# STM32G553 register map
File version: 2.0.0
CPU: CM33 r0p4, little endian, MPU, FPU, 4 interrupt priority bits
Registers are 32-bit, read-write, reset 0x0 unless marked. A register's access mark holds for its fields unless they carry their own. Offsets are from the block's base; [hi:lo] are bit positions; {n}, {i} and the like mark numbered series.

## POSENC1 — POSENC register block
Base 0x44010000
Same registers: POSENC2 0x44014000, POSENC1_S 0x54010000, POSENC2_S 0x54014000
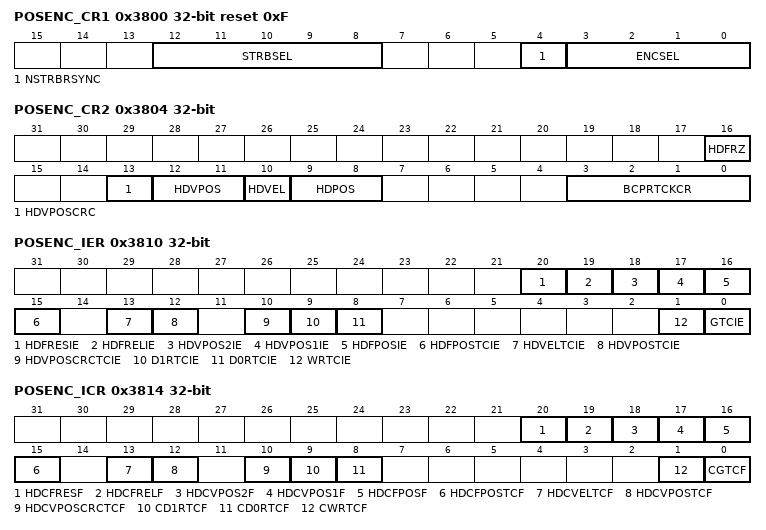
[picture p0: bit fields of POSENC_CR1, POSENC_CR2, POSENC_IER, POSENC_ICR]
0x3800 POSENC_CR1 rw-once reset 0xF — POSENC control register 1
  [12:8] STRBSEL rw — Strobe selection
    0=posenc_strb0; 1=posenc_strb1; 31=posenc_strb31
  [4] NSTRBRSYNC rw — Strobe re-synchronization
    0=Strobe re-synchronization enabled; 1=Strobe re-synchronization disabled
  [3:0] ENCSEL — Encoder selection
    0=EnDat3; 4=Hiperface-DSL; 15=No protocol selected
0x3804 POSENC_CR2 rw-once — POSENC control register 2
  [16] HDFRZ rw — Hiperface-DSL freeze
    0=Hiperface-DSL registers are not freezed; 1=Hiperface-DSL registers are freezed
  [13] HDVPOSCRC rw — Hiperface-DSL velocity event-driven accesses
    0=No safe position 1 CRC reading; 1=Safe position 1 CRC reading (VPOSCRC stored in POSENC_HD_VPOSCRC)
  [12:11] HDVPOS rw — Hiperface-DSL fast position event-driven accesses
    0=No safe position 1 reading; 1=Single-turn 17-bit safe position 1 reading (VPOS0..2 stored in POSENC_HD_VPOS3_0); 2=Single-turn 17-bit/multi-turn 12-bit safe position 1 reading (VPOS0..3 stored in POSENC_HD_VPOS3_0); 3=Single-turn 23-bit/multi-turn 12-bit safe position 1 reading (VPOS0..4 stored in POSENC_HD_VPOS3_0 and POSENC_HD_VPOS4)
  [10] HDVEL rw — Hiperface-DSL Velocity event-driven accesses
    0=No velocity reading; 1=Velocity reading (VEL0..2 stored in POSENC_HD_VEL2_0)
  [9:8] HDPOS rw — Hiperface-DSL fast position event-driven accesses
    0=No position reading; 1=Single-turn 17-bit position reading (POS0..2 stored in POSENC_HD_POS3_0); 2=Single-turn 17-bit/multi-turn 12-bit position reading (POS0..3 stored in POSENC_HD_POS3_0); 3=Single-turn 23-bit/multi-turn 12-bit position reading (POS0..4 stored in POSENC_HD_POS3_0 and POSENC_HD_POS4)
  [3:0] BCPRTCKCR — Biss-C specific
0x3810 POSENC_IER — POSENC interrupt enable register
  [20] HDFRESIE — Hiperface-DSL short message interrupt enable
    0=Hiperface-DSL short message interrupt disabled; 1=Hiperface-DSL short message interrupt enabled
  [19] HDFRELIE — Hiperface-DSL long message interrupt enable
    0=Hiperface-DSL long message interrupt disabled; 1=Hiperface-DSL long message interrupt enabled
  [18] HDVPOS2IE — Hiperface-DSL safe position 2 interrupt enable
    0=Hiperface-DSL safe position 2 interrupt disabled; 1=Hiperface-DSL safe position 2 interrupt enabled
  [17] HDVPOS1IE — Hiperface-DSL safe position 1 interrupt enable
    0=Hiperface-DSL safe position 1 interrupt disabled; 1=Hiperface-DSL safe position 1 interrupt enabled
  [16] HDFPOSIE — Hiperface-DSL fast position interrupt enable
    0=Hiperface-DSL fast position interrupt disabled; 1=Hiperface-DSL fast position interrupt enabled
  [15] HDFPOSTCIE — Hiperface-DSL fast position transfer complete interrupt enable
    0=Hiperface-DSL fast position transfer complete interrupt disabled; 1=Hiperface-DSL fast position transfer complete interrupt enabled
  [13] HDVELTCIE — Hiperface-DSL velocity transfer complete interrupt enable
    0=Hiperface-DSL velocity transfer complete interrupt disabled; 1=Hiperface-DSL velocity transfer complete interrupt enabled
  [12] HDVPOSTCIE — Hiperface-DSL safe position 1 transfer complete interrupt enable
    0=Hiperface-DSL safe position 1 transfer complete interrupt disabled; 1=Hiperface-DSL safe position 1 transfer complete interrupt enabled
  [10] HDVPOSCRCTCIE — Hiperface-DSL safe position 1 CRC transfer complete interrupt enable
    0=Hiperface-DSL safe position 1 CRC transfer complete interrupt disabled; 1=Hiperface-DSL safe position 1 CRC transfer complete interrupt enabled
  [9] D1RTCIE — Data 1 Read transfer complete interrupt enable
    0=Data 1 transfer complete interrupt disabled; 1=Data 1 transfer complete interrupt enabled
  [8] D0RTCIE — Read Data 0 transfer complete interrupt enable
    0=Data 0 transfer complete interrupt disabled; 1=Data 0 transfer complete interrupt enabled
  [1] WRTCIE — Write transfer complete interrupt enable
    0=Write transfer complete interrupt disabled; 1=Write transfer complete interrupt enabled
  [0] GTCIE — Global Transfer complete interrupt enable
    0=Global transfer complete interrupt disabled; 1=Global transfer complete interrupt enabled
0x3814 POSENC_ICR wo — POSENC interrupt clear register
  [20] HDCFRESF — Clear Hiperface-DSL short message interrupt flag
  [19] HDCFRELF — Clear Hiperface-DSL long message interrupt flag
  [18] HDCVPOS2F — Clear Hiperface-DSL safe position 2 interrupt flag
  [17] HDCVPOS1F — Clear Hiperface-DSL safe position 1 interrupt flag
  [16] HDCFPOSF — Clear Hiperface-DSL fast position interrupt flag
  [15] HDCFPOSTCF — Clear Hiperface-DSL fast position transfer complete interrupt flag
  [13] HDCVELTCF — Clear Hiperface-DSL velocity transfer complete interrupt flag
  [12] HDCVPOSTCF — Clear Hiperface-DSL safe position 1 transfer complete interrupt flag
  [10] HDCVPOSCRCTCF — Clear Hiperface-DSL safe position 1 CRC transfer complete interrupt flag
  [9] CD1RTCF — Clear data 1 read transfer complete interrupt flag
  [8] CD0RTCF — Clear data 0 read transfer complete interrupt flag
  [1] CWRTCF — Clear write transfer complete interrupt flag
  [0] CGTCF — Clear transfer complete interrupt flag
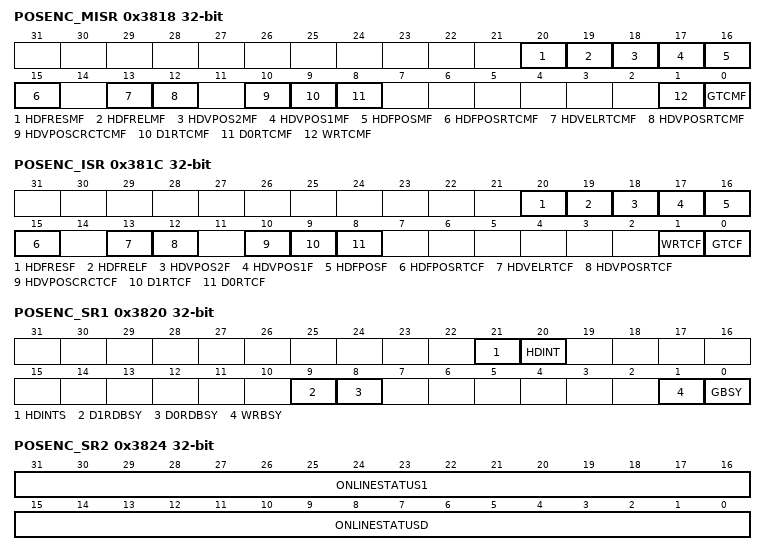
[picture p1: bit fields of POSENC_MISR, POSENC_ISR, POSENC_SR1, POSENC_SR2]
0x3818 POSENC_MISR — POSENC masked interrupt status register
  [20] HDFRESMF wo — Hiperface-DSL short message interrupt masked flag
  [19] HDFRELMF wo — Hiperface-DSL long message interrupt masked flag
  [18] HDVPOS2MF wo — Hiperface-DSL safe position 2 interrupt masked flag
  [17] HDVPOS1MF wo — Hiperface-DSL safe position 1 interrupt masked flag
  [16] HDFPOSMF wo — Hiperface-DSL fast position interrupt masked flag
  [15] HDFPOSRTCMF ro — Hiperface-DSL fast position 1 ready interrupt masked flag
  [13] HDVELRTCMF ro — Hiperface-DSL velocity ready interrupt masked flag
  [12] HDVPOSRTCMF ro — Hiperface-DSL safe position 1 transfer complete interrupt masked flag
  [10] HDVPOSCRCTCMF ro — Hiperface-DSL safe position 1 CRC transfer complete interrupt masked flag
  [9] D1RTCMF ro — Data 1 read transfer complete masked flag
  [8] D0RTCMF ro — Data 0 read transfer complete masked flag
  [1] WRTCMF ro — Write transfer complete masked flag
  [0] GTCMF ro — Global Transfer complete masked flag
0x381C POSENC_ISR — POSENC interrupt status register
  [20] HDFRESF wo — Hiperface-DSL short message interrupt flag
  [19] HDFRELF wo — Hiperface-DSL long message interrupt masked flag
  [18] HDVPOS2F wo — Hiperface-DSL safe position 2 interrupt flag
  [17] HDVPOS1F wo — Hiperface-DSL safe position 1 interrupt flag
  [16] HDFPOSF wo — Hiperface-DSL fast position interrupt flag
  [15] HDFPOSRTCF ro — Hiperface-DSL fast position transfer complete interrupt flag
  [13] HDVELRTCF ro — Hiperface-DSL velocity transfer complete interrupt flag
  [12] HDVPOSRTCF ro — Hiperface-DSL safe position 1 transfer complete interrupt flag
  [10] HDVPOSCRCTCF ro — Hiperface-DSL safe position 1 CRC transfer complete interrupt flag
  [9] D1RTCF ro — Data 1 read transfer complete flag
  [8] D0RTCF ro — Data 0 read transfer complete flag
  [1] WRTCF ro — Write transfer complete flag
  [0] GTCF ro — Global transfer complete flag
0x3820 POSENC_SR1 ro — POSENC interrupt status register 1
  [21] HDINTS — Hiperface-DSL interrupt_s line status
  [20] HDINT — Hiperface-DSL interrupt line status
  [9] D1RDBSY — Data 1 read busy
  [8] D0RDBSY — Data 0 read busy
  [1] WRBSY — Write busy
  [0] GBSY — Global busy
0x3824 POSENC_SR2 ro — POSENC interrupt status register 2
  [31:16] ONLINESTATUS1 — Online status safe 1 interface
  [15:0] ONLINESTATUSD — Online status safe 1 interface
0x3828 POSENC_SR3 ro — POSENC interrupt status register 3
  [15:0] ONLINESTATUS2 — Online status safe 2 interface
0x3A04 POSENC_D0AR — POSENC data 0 address register
  [7:0] D0ADD — Data 0 address
0x3A08 POSENC_D1AR — POSENC data 1 address register
  [7:0] D1ADD — Data 1 address
0x3B04 POSENC_D0R ro — POSENC data 0 register
  [31:0] D0 — Data 0 value
0x3B08 POSENC_D1R ro — POSENC data 1 register
  [31:0] D1 — Data 1 value
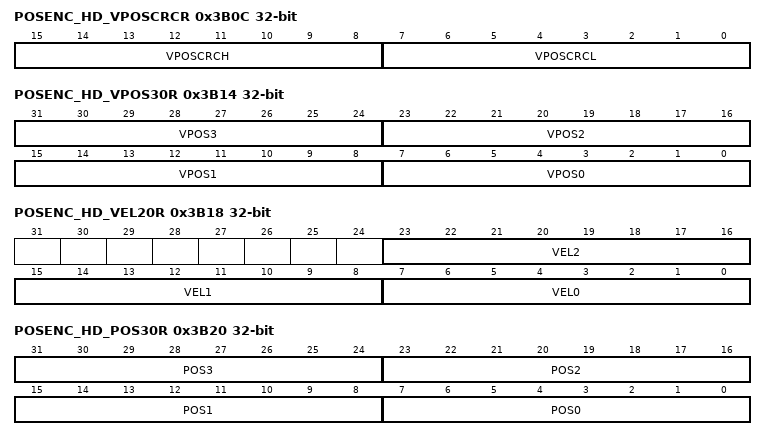
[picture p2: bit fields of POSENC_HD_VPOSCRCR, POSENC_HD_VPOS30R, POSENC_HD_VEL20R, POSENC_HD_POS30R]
0x3B0C POSENC_HD_VPOSCRCR ro — POSENC Hiperface-DSL safe position 1 CRC register
  [15:8] VPOSCRCH — Hiperface-DSL safe position 1 CRC value
  [7:0] VPOSCRCL — Hiperface-DSL safe position 1 CRC value
0x3B10 POSENC_HD_VPOS4R ro — POSENC Hiperface-DSL safe position 1 VPOS4 register
  [7:0] VPOS4 — Hiperface-DSL safe position 1 VPOS4 value
0x3B14 POSENC_HD_VPOS30R ro — POSENC Hiperface-DSL safe position 1 VPOS3_0 register
  [8n+7:8n] VPOS{n} (n=0..3) — Hiperface-DSL safe position 1 VPOS{n} value
0x3B18 POSENC_HD_VEL20R ro — POSENC Hiperface-DSL safe position 1 VEL2_0 register
  [23:16] VEL2 — Hiperface-DSL velocity VEL2 value
  [15:8] VEL1 — Hiperface-DSL velocity VEL1 value
  [7:0] VEL0 — Hiperface-DSL velocity VEL0 value
0x3B1C POSENC_HD_POS4R ro — POSENC Hiperface-DSL fast position POS4 register
  [7:0] POS4 — Hiperface-DSL fast position POS4 value
0x3B20 POSENC_HD_POS30R ro — POSENC Hiperface-DSL fast position POS3_0 register
  [8n+7:8n] POS{n} (n=0..3) — Hiperface-DSL fast position POS{n} value
